AUTOSAR XML (schema 4-2-1)
package /ComponentTypes
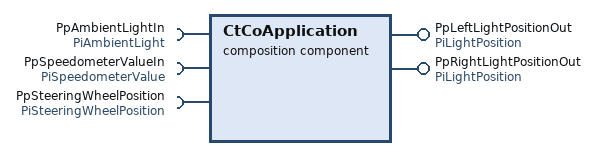
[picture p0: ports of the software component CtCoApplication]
  composition sw component type CtCoApplication
    provide port PpLeftLightPositionOut: provided-com-specs=[{data-element=DeLightLength, init-value=0}, {data-element=DeLightPosition, init-value=0}], provided-interface=PiLightPosition
    provide port PpRightLightPositionOut: provided-com-specs=[{data-element=DeLightLength, init-value=0}, {data-element=DeLightPosition, init-value=0}], provided-interface=PiLightPosition
    require port PpAmbientLightIn: nonqueued-receiver-com-spec{data-element=DeAmbientLight, filter=data-filter-type=ALWAYS, init-value=constant-reference=CDarkLight}, required-interface=PiAmbientLight
    require port PpSpeedometerValueIn: nonqueued-receiver-com-spec{data-element=DeSpeedometerValue, filter=data-filter-type=ALWAYS, init-value=constant-reference=CInitSpeed}, required-interface=PiSpeedometerValue
    require port PpSteeringWheelPosition: nonqueued-receiver-com-spec{data-element=DeSteeringWheelPosition, filter=data-filter-type=ALWAYS, init-value=constant-reference=CSteeringWheelInitPosition}, required-interface=PiSteeringWheelPosition
    8 x component:
      CpApAFSController: type=CtApAFSController
      CpApBatteryManager: type=CtApBatteryManager
      CpCddIoHwAb: type=CtCddIoHwAb
      CpSaAmbientLight: type=CtSaAmbientLight
      CpSaLeftFrontlight: type=CtSaFrontlight
      CpSaRightFrontlight: type=CtSaFrontlight
      CpSaSpeedometer: type=CtSaSpeedometer
      CpSaSteeringWheel: type=CtSaSteeringWheel
    connect CpApAFSController.PpLightPositionLeft -> CpSaLeftFrontlight.PpLightPositionIn
    connect CpApAFSController.PpLightPositionRight -> CpSaRightFrontlight.PpLightPositionIn
    connect CpApBatteryManager.PpBateryMode -> CpApAFSController.PpBateryMode
    connect CpCddIoHwAb.PpAFSSwitch -> CpApAFSController.PpAFSSwitch
    connect CpCddIoHwAb.PpHighBeam -> CpApAFSController.PpHighBeam
    connect CpCddIoHwAb.PpBatterySlider -> CpApBatteryManager.PpBatterySlider
    connect CpSaAmbientLight.PpAmbientLightOut -> CpApAFSController.PpAmbientLight
    connect CpSaSpeedometer.PpSpeedometerValueOut -> CpApAFSController.PpSpeedometerValue
    connect CpSaSteeringWheel.PpSteeringWheelPositionOut -> CpApAFSController.PpSteeringWheelPosition
    delegate CpSaAmbientLight.PpAmbientLightIn <-> outer port PpAmbientLightIn
    delegate CpSaLeftFrontlight.PpLightPositionOut <-> outer port PpLeftLightPositionOut
    delegate CpSaRightFrontlight.PpLightPositionOut <-> outer port PpRightLightPositionOut
    delegate CpSaSpeedometer.PpSpeedometerValueIn <-> outer port PpSpeedometerValueIn
    delegate CpSaSteeringWheel.PpSteeringWheelPositionIn <-> outer port PpSteeringWheelPosition
